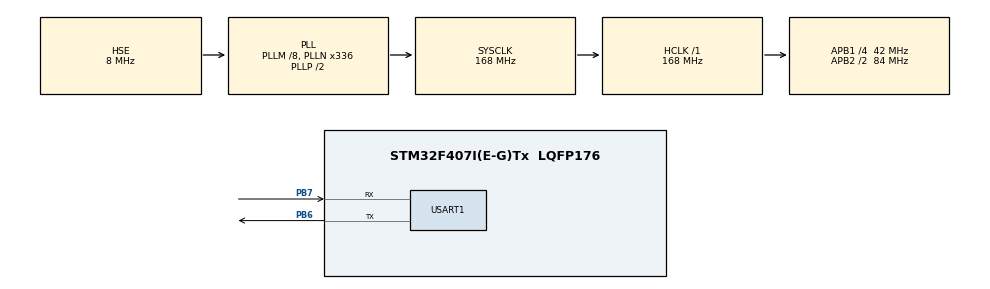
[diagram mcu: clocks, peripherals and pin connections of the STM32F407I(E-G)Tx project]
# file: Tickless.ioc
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FREERTOS.INCLUDE_xEventGroupSetBitFromISR=1
FREERTOS.INCLUDE_xTaskGetCurrentTaskHandle=1
FREERTOS.INCLUDE_xTimerPendFunctionCall=1
FREERTOS.Tasks01=HighTask,2,128,High_Task,Default,NULL,Dynamic,NULL,NULL;LowTask,-2,128,Low_Task,Default,NULL,Dynamic,NULL,NULL
FREERTOS.configUSE_TICKLESS_IDLE=1
FREERTOS.configUSE_TIMERS=1
Mcu.Family=STM32F4
Mcu.Name=STM32F407I(E-G)Tx
Mcu.Package=LQFP176
NVIC.PriorityGroup=NVIC_PRIORITYGROUP_4
NVIC.TIM1_UP_TIM10_IRQn=true\:15\:0\:false\:false\:true\:false\:false\:true\:true
NVIC.TimeBase=TIM1_UP_TIM10_IRQn
NVIC.TimeBaseIP=TIM1
PA13.Mode=Serial_Wire
PA13.Signal=SYS_JTMS-SWDIO
PA14.Mode=Serial_Wire
PA14.Signal=SYS_JTCK-SWCLK
PB6.Mode=Asynchronous
PB6.Signal=USART1_TX
PB7.Mode=Asynchronous
PB7.Signal=USART1_RX
PH0-OSC_IN.Mode=HSE-External-Oscillator
PH0-OSC_IN.Signal=RCC_OSC_IN
PH1-OSC_OUT.Mode=HSE-External-Oscillator
PH1-OSC_OUT.Signal=RCC_OSC_OUT
ProjectManager.HeapSize=0x200
ProjectManager.StackSize=0x400
ProjectManager.TargetToolchain=MDK-ARM V5.32
RCC.48MHZClocksFreq_Value=84000000
RCC.AHBFreq_Value=168000000
RCC.APB1CLKDivider=RCC_HCLK_DIV4
RCC.APB1Freq_Value=42000000
RCC.APB1TimFreq_Value=84000000
RCC.APB2CLKDivider=RCC_HCLK_DIV2
RCC.APB2Freq_Value=84000000
RCC.APB2TimFreq_Value=168000000
RCC.CortexFreq_Value=168000000
RCC.HCLKFreq_Value=168000000
RCC.HSE_VALUE=8000000
RCC.HSI_VALUE=16000000
RCC.LSE_VALUE=32768
RCC.PLLM=8
RCC.PLLN=336
RCC.PLLSourceVirtual=RCC_PLLSOURCE_HSE
RCC.SYSCLKFreq_VALUE=168000000
RCC.SYSCLKSource=RCC_SYSCLKSOURCE_PLLCLK
RCC.VCOOutputFreq_Value=336000000
USART1.VirtualMode=VM_ASYNC
VP_FREERTOS_VS_CMSIS_V1.Mode=CMSIS_V1
VP_SYS_VS_tim1.Mode=TIM1
board=custom

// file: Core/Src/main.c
/* USER CODE BEGIN Header */
/**
  ******************************************************************************
  * @file           : main.c
  * @brief          : Main program body
  ******************************************************************************
  * @attention
  *
  * Copyright (c) 2024 STMicroelectronics.
  * All rights reserved.
  *
  * This software is licensed under terms that can be found in the LICENSE file
  * in the root directory of this software component.
  * If no LICENSE file comes with this software, it is provided AS-IS.
  *
  ******************************************************************************
  */
/* USER CODE END Header */
#include "main.h"
#include "cmsis_os.h"
#include "usart.h"
#include "gpio.h"

void SystemClock_Config(void);
void MX_FREERTOS_Init(void);

int main(void)
{

  /* MCU Configuration--------------------------------------------------------*/

  /* Reset of all peripherals, Initializes the Flash interface and the Systick. */
  HAL_Init();

  /* Configure the system clock */
  SystemClock_Config();

  /* Initialize all configured peripherals */
  MX_GPIO_Init();
  MX_USART1_UART_Init();

  /* Call init function for freertos objects (in cmsis_os2.c) */
  MX_FREERTOS_Init();

  /* Start scheduler */
  osKernelStart();

  /* We should never get here as control is now taken by the scheduler */

  /* Infinite loop */
  while (1)
  {

  }
}

void SystemClock_Config(void)
{
  RCC_OscInitTypeDef RCC_OscInitStruct = {0};
  RCC_ClkInitTypeDef RCC_ClkInitStruct = {0};

  /** Configure the main internal regulator output voltage
  */
  __HAL_RCC_PWR_CLK_ENABLE();
  __HAL_PWR_VOLTAGESCALING_CONFIG(PWR_REGULATOR_VOLTAGE_SCALE1);

  /** Initializes the RCC Oscillators according to the specified parameters
  * in the RCC_OscInitTypeDef structure.
  */
  RCC_OscInitStruct.OscillatorType = RCC_OSCILLATORTYPE_HSE;
  RCC_OscInitStruct.HSEState = RCC_HSE_ON;
  RCC_OscInitStruct.PLL.PLLState = RCC_PLL_ON;
  RCC_OscInitStruct.PLL.PLLSource = RCC_PLLSOURCE_HSE;
  RCC_OscInitStruct.PLL.PLLM = 8;
  RCC_OscInitStruct.PLL.PLLN = 336;
  RCC_OscInitStruct.PLL.PLLP = RCC_PLLP_DIV2;
  RCC_OscInitStruct.PLL.PLLQ = 4;
  if (HAL_RCC_OscConfig(&RCC_OscInitStruct) != HAL_OK)
  {
    Error_Handler();
  }

  /** Initializes the CPU, AHB and APB buses clocks
  */
  RCC_ClkInitStruct.ClockType = RCC_CLOCKTYPE_HCLK|RCC_CLOCKTYPE_SYSCLK
                              |RCC_CLOCKTYPE_PCLK1|RCC_CLOCKTYPE_PCLK2;
  RCC_ClkInitStruct.SYSCLKSource = RCC_SYSCLKSOURCE_PLLCLK;
  RCC_ClkInitStruct.AHBCLKDivider = RCC_SYSCLK_DIV1;
  RCC_ClkInitStruct.APB1CLKDivider = RCC_HCLK_DIV4;
  RCC_ClkInitStruct.APB2CLKDivider = RCC_HCLK_DIV2;

  if (HAL_RCC_ClockConfig(&RCC_ClkInitStruct, FLASH_LATENCY_5) != HAL_OK)
  {
    Error_Handler();
  }
}

/* USER CODE BEGIN 4 */
//printf
int fputc(int ch, FILE *f)
{
    while((USART1->SR & 0X40)==0);
    USART1->DR = (uint8_t) ch;
    return ch;
}
/* USER CODE END 4 */

void HAL_TIM_PeriodElapsedCallback(TIM_HandleTypeDef *htim)
{
  if (htim->Instance == TIM1) {
    HAL_IncTick();
  }
}

void Error_Handler(void)
{
  __disable_irq();
  while (1)
  {
  }
}

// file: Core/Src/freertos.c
/* USER CODE BEGIN Header */
/**
  ******************************************************************************
  * File Name          : freertos.c
  * Description        : Code for freertos applications
  ******************************************************************************
  * @attention
  *
  * Copyright (c) 2024 STMicroelectronics.
  * All rights reserved.
  *
  * This software is licensed under terms that can be found in the LICENSE file
  * in the root directory of this software component.
  * If no LICENSE file comes with this software, it is provided AS-IS.
  *
  ******************************************************************************
  */
/* USER CODE END Header */

#include "FreeRTOS.h"
#include "task.h"
#include "main.h"
#include "cmsis_os.h"

osThreadId HighTaskHandle;
osThreadId LowTaskHandle;

void High_Task(void const * argument);
void Low_Task(void const * argument);

void MX_FREERTOS_Init(void); /* (MISRA C 2004 rule 8.1) */

/* GetIdleTaskMemory prototype (linked to static allocation support) */
void vApplicationGetIdleTaskMemory( StaticTask_t **ppxIdleTaskTCBBuffer, StackType_t **ppxIdleTaskStackBuffer, uint32_t *pulIdleTaskStackSize );

/* GetTimerTaskMemory prototype (linked to static allocation support) */
void vApplicationGetTimerTaskMemory( StaticTask_t **ppxTimerTaskTCBBuffer, StackType_t **ppxTimerTaskStackBuffer, uint32_t *pulTimerTaskStackSize );

/* USER CODE BEGIN PREPOSTSLEEP */
__weak void PreSleepProcessing(uint32_t ulExpectedIdleTime)
{
/* place for user code */
		//����ǰ
	printf("Before enter sleep mode! ulExpectedIdleTime = %u\n", ulExpectedIdleTime);
	HAL_SuspendTick();
}

__weak void PostSleepProcessing(uint32_t ulExpectedIdleTime)
{
/* place for user code */
		//���ߺ�
	printf("Already enter sleep mode! ulExpectedIdleTime = %u\n", ulExpectedIdleTime);
	//HAL_ResumeTick();
}
/* USER CODE END PREPOSTSLEEP */

/* USER CODE BEGIN GET_IDLE_TASK_MEMORY */
static StaticTask_t xIdleTaskTCBBuffer;
static StackType_t xIdleStack[configMINIMAL_STACK_SIZE];

void vApplicationGetIdleTaskMemory( StaticTask_t **ppxIdleTaskTCBBuffer, StackType_t **ppxIdleTaskStackBuffer, uint32_t *pulIdleTaskStackSize )
{
  *ppxIdleTaskTCBBuffer = &xIdleTaskTCBBuffer;
  *ppxIdleTaskStackBuffer = &xIdleStack[0];
  *pulIdleTaskStackSize = configMINIMAL_STACK_SIZE;
  /* place for user code */
}
/* USER CODE END GET_IDLE_TASK_MEMORY */

/* USER CODE BEGIN GET_TIMER_TASK_MEMORY */
static StaticTask_t xTimerTaskTCBBuffer;
static StackType_t xTimerStack[configTIMER_TASK_STACK_DEPTH];

void vApplicationGetTimerTaskMemory( StaticTask_t **ppxTimerTaskTCBBuffer, StackType_t **ppxTimerTaskStackBuffer, uint32_t *pulTimerTaskStackSize )
{
  *ppxTimerTaskTCBBuffer = &xTimerTaskTCBBuffer;
  *ppxTimerTaskStackBuffer = &xTimerStack[0];
  *pulTimerTaskStackSize = configTIMER_TASK_STACK_DEPTH;
  /* place for user code */
}
/* USER CODE END GET_TIMER_TASK_MEMORY */

void MX_FREERTOS_Init(void) {

  /* Create the thread(s) */
  /* definition and creation of HighTask */
  osThreadDef(HighTask, High_Task, osPriorityHigh, 0, 128);
  HighTaskHandle = osThreadCreate(osThread(HighTask), NULL);

  /* definition and creation of LowTask */
  osThreadDef(LowTask, Low_Task, osPriorityLow, 0, 128);
  LowTaskHandle = osThreadCreate(osThread(LowTask), NULL);

}

void High_Task(void const * argument)
{
  /* USER CODE BEGIN High_Task */
  /* Infinite loop */
  for(;;)
  {
    osDelay(10);
  }
  /* USER CODE END High_Task */
}

void Low_Task(void const * argument)
{
  /* USER CODE BEGIN Low_Task */
  /* Infinite loop */
  for(;;)
  {
    osDelay(20);
  }
  /* USER CODE END Low_Task */
}
